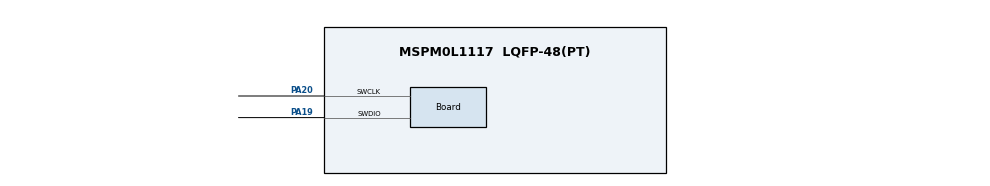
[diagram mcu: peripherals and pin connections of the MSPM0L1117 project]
//@cliArgs --device "MSPM0L111X" --package "LQFP-48(PT)" --part "Default"
//@v2CliArgs --device "MSPM0L1117" --package "LQFP-48(PT)"
// @cliArgs --board /ti/boards/LP_MSPM0L1117 --rtos nortos

/**
 * Import the modules used in this configuration.
 */
const PWM  = scripting.addModule("/ti/driverlib/PWM", {}, false);
const PWM1 = PWM.addInstance();

/**
 * Write custom configuration values to the imported modules.
 */
PWM1.$name                          = "PWM_0";
PWM1.clockDivider                   = 2;
PWM1.timerCount                     = 1024;
PWM1.ccIndex                        = [0];
PWM1.interrupts                     = ["CC0_DN_EVENT"];
PWM1.enableShadowLoad               = true;
PWM1.peripheral.$assign             = "TIMA0";
PWM1.PWM_CHANNEL_0.$name            = "ti_driverlib_pwm_PWMTimerCC0";
PWM1.PWM_CHANNEL_0.ccValue          = 1023;
PWM1.PWM_CHANNEL_0.shadowUpdateMode = "COMP_DN_EVT";

const Board                       = scripting.addModule("/ti/driverlib/Board", {}, false);
Board.peripheral.$assign          = "DEBUGSS";
Board.peripheral.swclkPin.$assign = "PA20";
Board.peripheral.swdioPin.$assign = "PA19";

const SYSCTL              = scripting.addModule("/ti/driverlib/SYSCTL", {}, false);
SYSCTL.peripheral.$assign = "SYSCTL";

const ProjectConfig              = scripting.addModule("/ti/project_config/ProjectConfig", {}, false);
ProjectConfig.migrationCondition = true;
